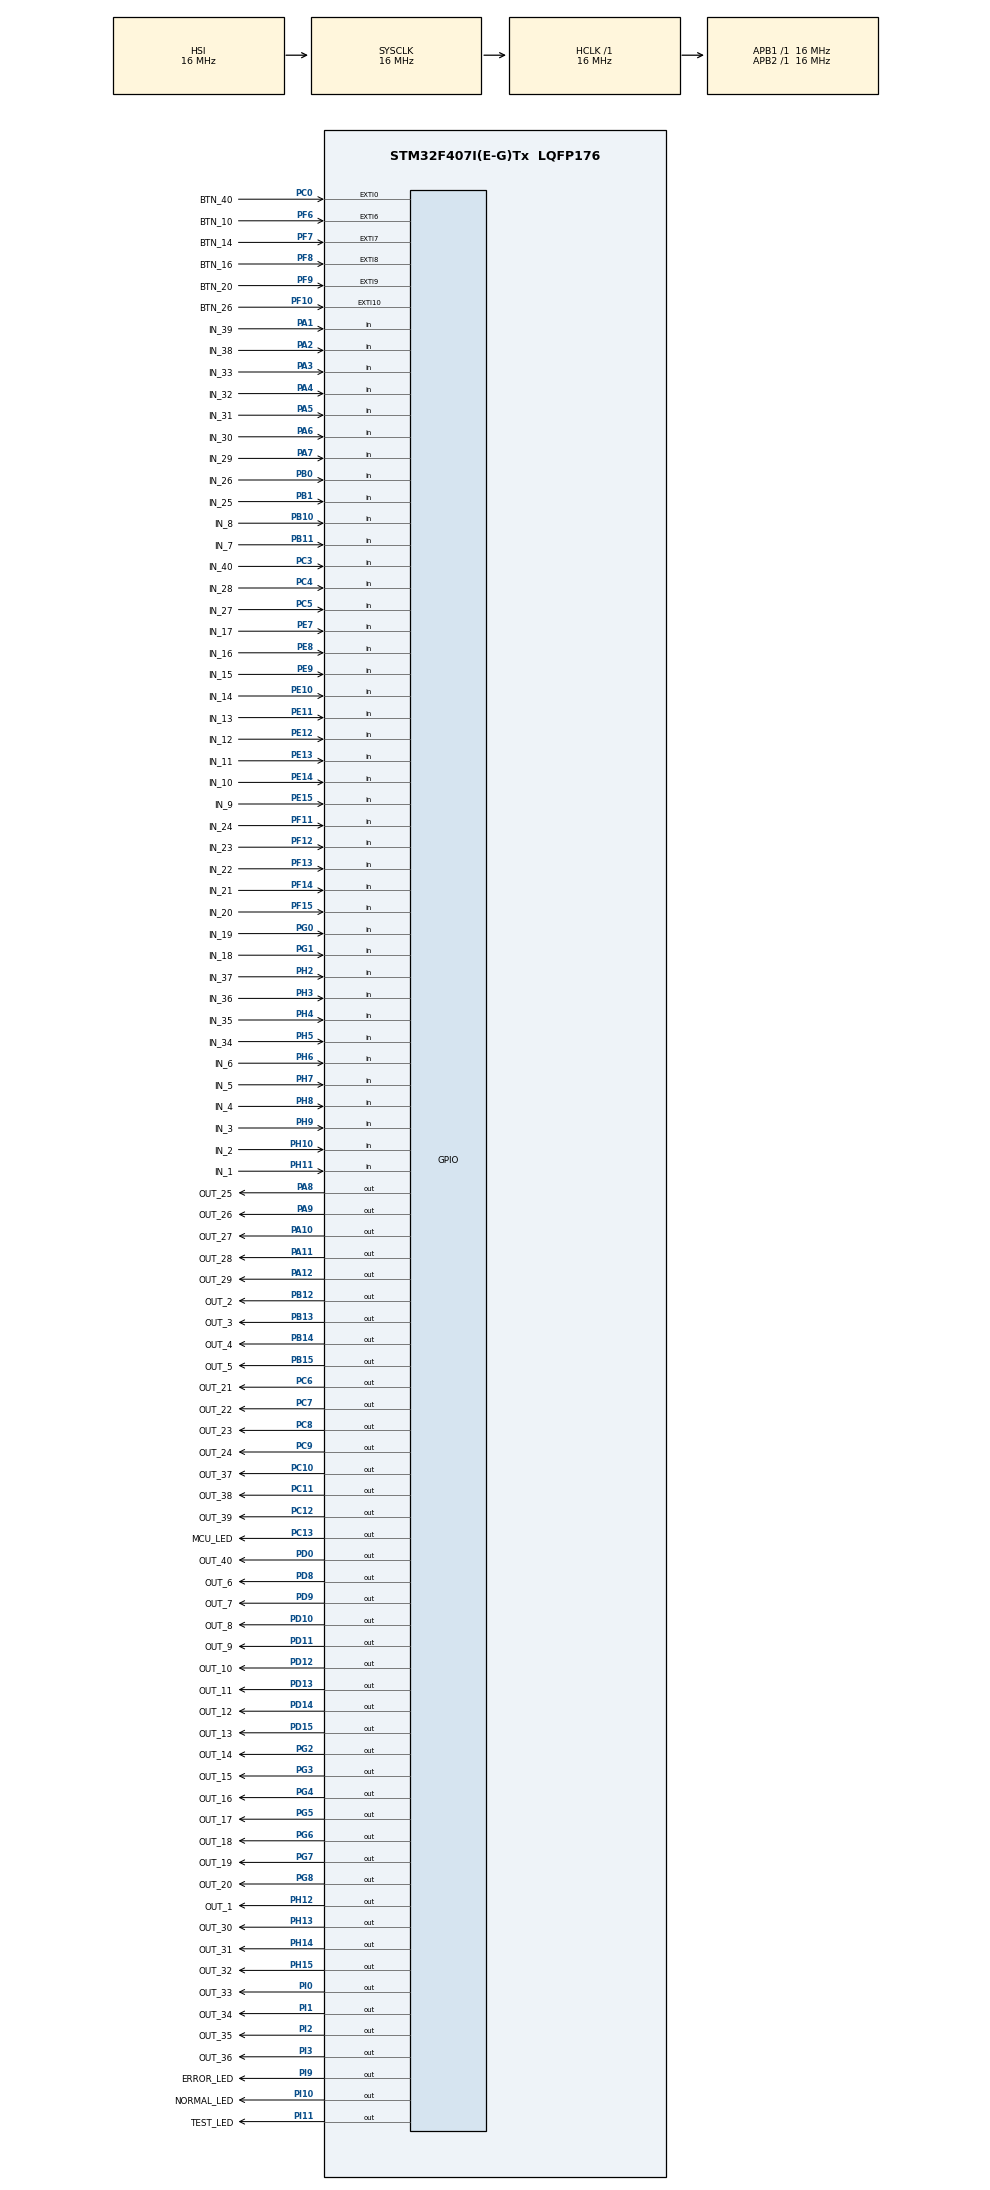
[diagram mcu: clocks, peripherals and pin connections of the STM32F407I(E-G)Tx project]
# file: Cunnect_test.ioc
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Mcu.Family=STM32F4
Mcu.Name=STM32F407I(E-G)Tx
Mcu.Package=LQFP176
NVIC.EXTI0_IRQn=true\:0\:0\:false\:false\:true\:true\:true\:true
NVIC.EXTI15_10_IRQn=true\:0\:0\:false\:false\:true\:true\:true\:true
NVIC.EXTI9_5_IRQn=true\:0\:0\:false\:false\:true\:true\:true\:true
NVIC.PriorityGroup=NVIC_PRIORITYGROUP_4
NVIC.TIM2_IRQn=true\:0\:0\:false\:false\:true\:true\:true\:true
PA1.GPIO_Label=IN_39
PA1.GPIO_PuPd=GPIO_PULLDOWN
PA1.Signal=GPIO_Input
PA10.GPIO_Label=OUT_27
PA10.Signal=GPIO_Output
PA11.GPIO_Label=OUT_28
PA11.Signal=GPIO_Output
PA12.GPIO_Label=OUT_29
PA12.Signal=GPIO_Output
PA13.Mode=JTAG_5_pins
PA13.Signal=SYS_JTMS-SWDIO
PA14.Mode=JTAG_5_pins
PA14.Signal=SYS_JTCK-SWCLK
PA15.Mode=JTAG_5_pins
PA15.Signal=SYS_JTDI
PA2.GPIO_Label=IN_38
PA2.GPIO_PuPd=GPIO_PULLDOWN
PA2.Signal=GPIO_Input
PA3.GPIO_Label=IN_33
PA3.GPIO_PuPd=GPIO_PULLDOWN
PA3.Signal=GPIO_Input
PA4.GPIO_Label=IN_32
PA4.GPIO_PuPd=GPIO_PULLDOWN
PA4.Signal=GPIO_Input
PA5.GPIO_Label=IN_31
PA5.GPIO_PuPd=GPIO_PULLDOWN
PA5.Signal=GPIO_Input
PA6.GPIO_Label=IN_30
PA6.GPIO_PuPd=GPIO_PULLDOWN
PA6.Signal=GPIO_Input
PA7.GPIO_Label=IN_29
PA7.GPIO_PuPd=GPIO_PULLDOWN
PA7.Signal=GPIO_Input
PA8.GPIO_Label=OUT_25
PA8.Signal=GPIO_Output
PA9.GPIO_Label=OUT_26
PA9.Signal=GPIO_Output
PB0.GPIO_Label=IN_26
PB0.GPIO_PuPd=GPIO_PULLDOWN
PB0.Signal=GPIO_Input
PB1.GPIO_Label=IN_25
PB1.GPIO_PuPd=GPIO_PULLDOWN
PB1.Signal=GPIO_Input
PB10.GPIO_Label=IN_8
PB10.GPIO_PuPd=GPIO_PULLDOWN
PB10.Signal=GPIO_Input
PB11.GPIO_Label=IN_7
PB11.GPIO_PuPd=GPIO_PULLDOWN
PB11.Signal=GPIO_Input
PB12.GPIO_Label=OUT_2
PB12.Signal=GPIO_Output
PB13.GPIO_Label=OUT_3
PB13.Signal=GPIO_Output
PB14.GPIO_Label=OUT_4
PB14.Signal=GPIO_Output
PB15.GPIO_Label=OUT_5
PB15.Signal=GPIO_Output
PB3.Mode=JTAG_5_pins
PB3.Signal=SYS_JTDO-SWO
PB4.Mode=JTAG_5_pins
PB4.Signal=SYS_JTRST
PC0.GPIO_Label=BTN_40
PC0.GPIO_ModeDefaultEXTI=GPIO_MODE_IT_FALLING
PC0.GPIO_PuPd=GPIO_NOPULL
PC0.Signal=GPXTI0
PC10.GPIO_Label=OUT_37
PC10.Signal=GPIO_Output
PC11.GPIO_Label=OUT_38
PC11.Signal=GPIO_Output
PC12.GPIO_Label=OUT_39
PC12.Signal=GPIO_Output
PC13-ANTI_TAMP.GPIO_Label=MCU_LED
PC13-ANTI_TAMP.PinState=GPIO_PIN_SET
PC13-ANTI_TAMP.Signal=GPIO_Output
PC3.GPIO_Label=IN_40
PC3.GPIO_PuPd=GPIO_PULLDOWN
PC3.Signal=GPIO_Input
PC4.GPIO_Label=IN_28
PC4.GPIO_PuPd=GPIO_PULLDOWN
PC4.Signal=GPIO_Input
PC5.GPIO_Label=IN_27
PC5.GPIO_PuPd=GPIO_PULLDOWN
PC5.Signal=GPIO_Input
PC6.GPIO_Label=OUT_21
PC6.Signal=GPIO_Output
PC7.GPIO_Label=OUT_22
PC7.Signal=GPIO_Output
PC8.GPIO_Label=OUT_23
PC8.Signal=GPIO_Output
PC9.GPIO_Label=OUT_24
PC9.Signal=GPIO_Output
PD0.GPIO_Label=OUT_40
PD0.Signal=GPIO_Output
PD10.GPIO_Label=OUT_8
PD10.Signal=GPIO_Output
PD11.GPIO_Label=OUT_9
PD11.Signal=GPIO_Output
PD12.GPIO_Label=OUT_10
PD12.Signal=GPIO_Output
PD13.GPIO_Label=OUT_11
PD13.Signal=GPIO_Output
PD14.GPIO_Label=OUT_12
PD14.Signal=GPIO_Output
PD15.GPIO_Label=OUT_13
PD15.Signal=GPIO_Output
PD8.GPIO_Label=OUT_6
PD8.Signal=GPIO_Output
PD9.GPIO_Label=OUT_7
PD9.Signal=GPIO_Output
PE10.GPIO_Label=IN_14
PE10.GPIO_PuPd=GPIO_PULLDOWN
PE10.Signal=GPIO_Input
PE11.GPIO_Label=IN_13
PE11.GPIO_PuPd=GPIO_PULLDOWN
PE11.Signal=GPIO_Input
PE12.GPIO_Label=IN_12
PE12.GPIO_PuPd=GPIO_PULLDOWN
PE12.Signal=GPIO_Input
PE13.GPIO_Label=IN_11
PE13.GPIO_PuPd=GPIO_PULLDOWN
PE13.Signal=GPIO_Input
PE14.GPIO_Label=IN_10
PE14.GPIO_PuPd=GPIO_PULLDOWN
PE14.Signal=GPIO_Input
PE15.GPIO_Label=IN_9
PE15.GPIO_PuPd=GPIO_PULLDOWN
PE15.Signal=GPIO_Input
PE7.GPIO_Label=IN_17
PE7.GPIO_PuPd=GPIO_PULLDOWN
PE7.Signal=GPIO_Input
PE8.GPIO_Label=IN_16
PE8.GPIO_PuPd=GPIO_PULLDOWN
PE8.Signal=GPIO_Input
PE9.GPIO_Label=IN_15
PE9.GPIO_PuPd=GPIO_PULLDOWN
PE9.Signal=GPIO_Input
PF10.GPIO_Label=BTN_26
PF10.GPIO_ModeDefaultEXTI=GPIO_MODE_IT_FALLING
PF10.GPIO_PuPd=GPIO_NOPULL
PF10.Signal=GPXTI10
PF11.GPIO_Label=IN_24
PF11.GPIO_PuPd=GPIO_NOPULL
PF11.Signal=GPIO_Input
PF12.GPIO_Label=IN_23
PF12.GPIO_PuPd=GPIO_NOPULL
PF12.Signal=GPIO_Input
PF13.GPIO_Label=IN_22
PF13.GPIO_PuPd=GPIO_NOPULL
PF13.Signal=GPIO_Input
PF14.GPIO_Label=IN_21
PF14.GPIO_PuPd=GPIO_NOPULL
PF14.Signal=GPIO_Input
PF15.GPIO_Label=IN_20
PF15.GPIO_PuPd=GPIO_NOPULL
PF15.Signal=GPIO_Input
PF6.GPIO_Label=BTN_10
PF6.GPIO_ModeDefaultEXTI=GPIO_MODE_IT_FALLING
PF6.GPIO_PuPd=GPIO_NOPULL
PF6.Signal=GPXTI6
PF7.GPIO_Label=BTN_14
PF7.GPIO_ModeDefaultEXTI=GPIO_MODE_IT_FALLING
PF7.GPIO_PuPd=GPIO_NOPULL
PF7.Signal=GPXTI7
PF8.GPIO_Label=BTN_16
PF8.GPIO_ModeDefaultEXTI=GPIO_MODE_IT_FALLING
PF8.GPIO_PuPd=GPIO_NOPULL
PF8.Signal=GPXTI8
PF9.GPIO_Label=BTN_20
PF9.GPIO_ModeDefaultEXTI=GPIO_MODE_IT_FALLING
PF9.GPIO_PuPd=GPIO_NOPULL
PF9.Signal=GPXTI9
PG0.GPIO_Label=IN_19
PG0.GPIO_PuPd=GPIO_NOPULL
PG0.Signal=GPIO_Input
PG1.GPIO_Label=IN_18
PG1.GPIO_PuPd=GPIO_NOPULL
PG1.Signal=GPIO_Input
PG2.GPIO_Label=OUT_14
PG2.Signal=GPIO_Output
PG3.GPIO_Label=OUT_15
PG3.Signal=GPIO_Output
PG4.GPIO_Label=OUT_16
PG4.Signal=GPIO_Output
PG5.GPIO_Label=OUT_17
PG5.Signal=GPIO_Output
PG6.GPIO_Label=OUT_18
PG6.Signal=GPIO_Output
PG7.GPIO_Label=OUT_19
PG7.Signal=GPIO_Output
PG8.GPIO_Label=OUT_20
PG8.Signal=GPIO_Output
PH10.GPIO_Label=IN_2
PH10.GPIO_PuPd=GPIO_NOPULL
PH10.Signal=GPIO_Input
PH11.GPIO_Label=IN_1
PH11.GPIO_PuPd=GPIO_NOPULL
PH11.Signal=GPIO_Input
PH12.GPIO_Label=OUT_1
PH12.Signal=GPIO_Output
PH13.GPIO_Label=OUT_30
PH13.Signal=GPIO_Output
PH14.GPIO_Label=OUT_31
PH14.Signal=GPIO_Output
PH15.GPIO_Label=OUT_32
PH15.Signal=GPIO_Output
PH2.GPIO_Label=IN_37
PH2.GPIO_PuPd=GPIO_NOPULL
PH2.Signal=GPIO_Input
PH3.GPIO_Label=IN_36
PH3.GPIO_PuPd=GPIO_NOPULL
PH3.Signal=GPIO_Input
PH4.GPIO_Label=IN_35
PH4.GPIO_PuPd=GPIO_NOPULL
PH4.Signal=GPIO_Input
PH5.GPIO_Label=IN_34
PH5.GPIO_PuPd=GPIO_NOPULL
PH5.Signal=GPIO_Input
PH6.GPIO_Label=IN_6
PH6.GPIO_PuPd=GPIO_NOPULL
PH6.Signal=GPIO_Input
PH7.GPIO_Label=IN_5
PH7.GPIO_PuPd=GPIO_NOPULL
PH7.Signal=GPIO_Input
PH8.GPIO_Label=IN_4
PH8.GPIO_PuPd=GPIO_NOPULL
PH8.Signal=GPIO_Input
PH9.GPIO_Label=IN_3
PH9.GPIO_PuPd=GPIO_NOPULL
PH9.Signal=GPIO_Input
PI0.GPIO_Label=OUT_33
PI0.Signal=GPIO_Output
PI1.GPIO_Label=OUT_34
PI1.Signal=GPIO_Output
PI10.GPIO_Label=NORMAL_LED
PI10.PinState=GPIO_PIN_SET
PI10.Signal=GPIO_Output
PI11.GPIO_Label=TEST_LED
PI11.PinState=GPIO_PIN_SET
PI11.Signal=GPIO_Output
PI2.GPIO_Label=OUT_35
PI2.Signal=GPIO_Output
PI3.GPIO_Label=OUT_36
PI3.Signal=GPIO_Output
PI9.GPIO_Label=ERROR_LED
PI9.PinState=GPIO_PIN_SET
PI9.Signal=GPIO_Output
ProjectManager.HeapSize=0x200
ProjectManager.StackSize=0x400
ProjectManager.TargetToolchain=STM32CubeIDE
RCC.AHBFreq_Value=16000000
RCC.APB1Freq_Value=16000000
RCC.APB2Freq_Value=16000000
RCC.CortexFreq_Value=16000000
RCC.HSE_VALUE=25000000
RCC.HSI_VALUE=16000000
RCC.LSE_VALUE=32768
RCC.SYSCLKFreq_VALUE=16000000
RCC.VCOOutputFreq_Value=192000000
TIM2.Period=2000-1
TIM2.Prescaler=1600-1
VP_TIM2_VS_ClockSourceINT.Mode=Internal
board=custom

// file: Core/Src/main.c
/* USER CODE BEGIN Header */
/**
  ******************************************************************************
  * @file           : main.c
  * @brief          : Main program body
  ******************************************************************************
  * @attention
  *
  * Copyright (c) 2024 STMicroelectronics.
  * All rights reserved.
  *
  * This software is licensed under terms that can be found in the LICENSE file
  * in the root directory of this software component.
  * If no LICENSE file comes with this software, it is provided AS-IS.
  *
  ******************************************************************************
  */
/* USER CODE END Header */
#include "main.h"
#include "tim.h"
#include "gpio.h"

/* USER CODE BEGIN Includes */
#include "check.h"

/* USER CODE END Includes */

/* USER CODE BEGIN PTD */

//IN 핀이랑 OUT 핀이랑 정

/* USER CODE END PTD */

void SystemClock_Config(void);

/* USER CODE BEGIN 0 */
uint32_t gpio_count = 0;
uint32_t blink_count = 0;
uint8_t error_count = 0;
uint32_t test_state = 0;
/* USER CODE END 0 */

int main(void)
{

  /* MCU Configuration--------------------------------------------------------*/

  /* Reset of all peripherals, Initializes the Flash interface and the Systick. */
  HAL_Init();

  /* Configure the system clock */
  SystemClock_Config();

  /* Initialize all configured peripherals */
  MX_GPIO_Init();
  MX_TIM2_Init();
  /* USER CODE BEGIN 2 */
  LED_SETTING();
  /* USER CODE END 2 */

  /* Infinite loop */
  /* USER CODE BEGIN WHILE */
  while (1)
  {
		result_connect();
    /* USER CODE END WHILE */

  }
}

void SystemClock_Config(void)
{
  RCC_OscInitTypeDef RCC_OscInitStruct = {0};
  RCC_ClkInitTypeDef RCC_ClkInitStruct = {0};

  /** Configure the main internal regulator output voltage
  */
  __HAL_RCC_PWR_CLK_ENABLE();
  __HAL_PWR_VOLTAGESCALING_CONFIG(PWR_REGULATOR_VOLTAGE_SCALE1);

  /** Initializes the RCC Oscillators according to the specified parameters
  * in the RCC_OscInitTypeDef structure.
  */
  RCC_OscInitStruct.OscillatorType = RCC_OSCILLATORTYPE_HSI;
  RCC_OscInitStruct.HSIState = RCC_HSI_ON;
  RCC_OscInitStruct.HSICalibrationValue = RCC_HSICALIBRATION_DEFAULT;
  RCC_OscInitStruct.PLL.PLLState = RCC_PLL_NONE;
  if (HAL_RCC_OscConfig(&RCC_OscInitStruct) != HAL_OK)
  {
    Error_Handler();
  }

  /** Initializes the CPU, AHB and APB buses clocks
  */
  RCC_ClkInitStruct.ClockType = RCC_CLOCKTYPE_HCLK|RCC_CLOCKTYPE_SYSCLK
                              |RCC_CLOCKTYPE_PCLK1|RCC_CLOCKTYPE_PCLK2;
  RCC_ClkInitStruct.SYSCLKSource = RCC_SYSCLKSOURCE_HSI;
  RCC_ClkInitStruct.AHBCLKDivider = RCC_SYSCLK_DIV1;
  RCC_ClkInitStruct.APB1CLKDivider = RCC_HCLK_DIV1;
  RCC_ClkInitStruct.APB2CLKDivider = RCC_HCLK_DIV1;

  if (HAL_RCC_ClockConfig(&RCC_ClkInitStruct, FLASH_LATENCY_0) != HAL_OK)
  {
    Error_Handler();
  }
}

void Error_Handler(void)
{
  __disable_irq();
  while (1)
  {
  }
}
